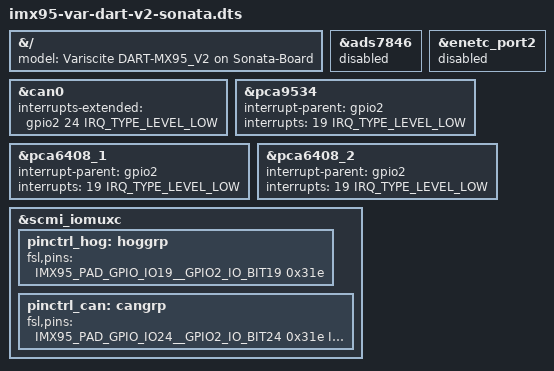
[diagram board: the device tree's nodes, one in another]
// SPDX-License-Identifier: (GPL-2.0+ OR MIT)
/*
 * Variscite Sonata carrier board for DART-MX95_V2
 *
 * Link: https://variscite.com/carrier-boards/sonata-board/
 *
 * Copyright (C) 2026 Variscite Ltd. - https://www.variscite.com/
 *
 */

#include "imx95-var-dart-sonata.dts"
#include "imx95-var-dart-v2.dtsi"

&{/} {
	model = "Variscite DART-MX95_V2 on Sonata-Board";
};

/*
 * J3.54 (touch IRQ) and J3.58 (CAN IRQ) map to the same SoM GPIO.
 * Use the GPIO for CAN IRQ and disable touch.
 */
&ads7846 {
	status = "disabled";
};

&can0 {
	interrupts-extended = <&gpio2 24 IRQ_TYPE_LEVEL_LOW>;
};

&enetc_port2 {
	status = "disabled";
};

&pca9534 {
	interrupt-parent = <&gpio2>;
	interrupts = <19 IRQ_TYPE_LEVEL_LOW>;
};

&pca6408_1 {
	interrupt-parent = <&gpio2>;
	interrupts = <19 IRQ_TYPE_LEVEL_LOW>;
};

&pca6408_2 {
	interrupt-parent = <&gpio2>;
	interrupts = <19 IRQ_TYPE_LEVEL_LOW>;
};

&scmi_iomuxc {
	pinctrl_hog: hoggrp {
		fsl,pins = <
			/* GPIO Expanders shared IRQ */
			IMX95_PAD_GPIO_IO19__GPIO2_IO_BIT19				0x31e
		>;
	};

	pinctrl_can: cangrp {
		fsl,pins = <
			IMX95_PAD_GPIO_IO24__GPIO2_IO_BIT24				0x31e
			IMX95_PAD_GPIO_IO22__GPIO2_IO_BIT22				0x31e
		>;
	};
};
